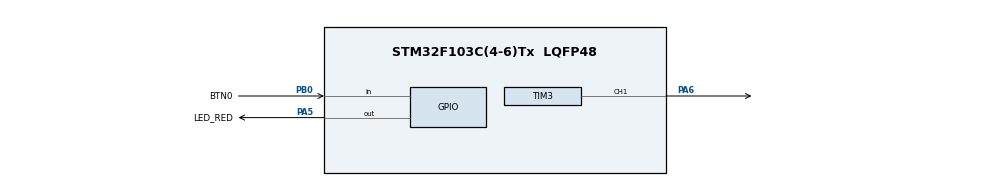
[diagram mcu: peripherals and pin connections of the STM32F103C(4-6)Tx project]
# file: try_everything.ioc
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Mcu.Family=STM32F1
Mcu.Name=STM32F103C(4-6)Tx
Mcu.Package=LQFP48
NVIC.PriorityGroup=NVIC_PRIORITYGROUP_4
NVIC.TIM2_IRQn=true\:0\:0\:false\:false\:true\:true\:true
NVIC.TIM3_IRQn=true\:0\:0\:false\:false\:true\:true\:true
PA5.GPIO_Label=LED_RED
PA5.Signal=GPIO_Output
PA6.Signal=S_TIM3_CH1
PB0.GPIO_Label=BTN0
PB0.Signal=GPIO_Input
PD0-OSC_IN.Mode=HSE-External-Oscillator
PD0-OSC_IN.Signal=RCC_OSC_IN
PD1-OSC_OUT.Mode=HSE-External-Oscillator
PD1-OSC_OUT.Signal=RCC_OSC_OUT
ProjectManager.HeapSize=0x200
ProjectManager.StackSize=0x400
ProjectManager.TargetToolchain=STM32CubeIDE
RCC.APB1Freq_Value=8000000
RCC.APB2Freq_Value=8000000
SH.S_TIM3_CH1.0=TIM3_CH1,PWM Generation1 CH1
TIM2.Period=9
TIM2.Prescaler=7999
TIM3.Channel-PWM\ Generation1\ CH1=TIM_CHANNEL_1
TIM3.Period=999
TIM3.Prescaler=7
VP_SYS_VS_ND.Mode=No_Debug
VP_TIM2_VS_ClockSourceINT.Mode=Internal
VP_TIM3_VS_ClockSourceINT.Mode=Internal
board=custom

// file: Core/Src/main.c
/* USER CODE BEGIN Header */
/**
  ******************************************************************************
  * @file           : main.c
  * @brief          : Main program body
  ******************************************************************************
  * @attention
  *
  * Copyright (c) 2021 STMicroelectronics.
  * All rights reserved.
  *
  * This software is licensed under terms that can be found in the LICENSE file
  * in the root directory of this software component.
  * If no LICENSE file comes with this software, it is provided AS-IS.
  *
  ******************************************************************************
  */
/* USER CODE END Header */
#include "main.h"

/* USER CODE BEGIN Includes */
#include "timer.h"
#include "button.h"
#include <stdio.h>
/* USER CODE END Includes */

/* USER CODE BEGIN PTD */
#define	OFF	 1
#define	DIM	 2
#define	MED	 3
#define	MAX	 4

static int led_state = OFF;
/* USER CODE END PTD */

TIM_HandleTypeDef htim2;
TIM_HandleTypeDef htim3;

void SystemClock_Config(void);
static void MX_GPIO_Init(void);
static void MX_TIM2_Init(void);
static void MX_TIM3_Init(void);

/* USER CODE BEGIN 0 */

void LED_LIGHT(int level) {
	switch(level) {
	case 0:
		__HAL_TIM_SetCompare(&htim3,TIM_CHANNEL_1,999);
		break;
	case 1:
		__HAL_TIM_SetCompare(&htim3,TIM_CHANNEL_1,749);
		break;
	case 2:
		__HAL_TIM_SetCompare(&htim3,TIM_CHANNEL_1,499);
		break;
	case 3:
		__HAL_TIM_SetCompare(&htim3,TIM_CHANNEL_1,0);
		break;
	}
}

void fsm_light() {
	switch(led_state) {
	case OFF:
		LED_LIGHT(0);
		if (get_button_value(0) == PRESS && get_button_delay(0) == 0) {
			set_button_delay(0);
			led_state = DIM;
		}
		break;
	case DIM:
		LED_LIGHT(1);
		if (get_button_value(0) == PRESS && get_button_delay(0) == 0) {
			set_button_delay(0);
			led_state = MED;
		}
		if (get_button_value(1) == PRESS) {
			led_state = OFF;
		}
		break;
	case MED:
		LED_LIGHT(2);
		if (get_button_value(0) == PRESS && get_button_delay(0) == 0) {
			set_button_delay(0);
			led_state = MAX;
		}
		if (get_button_value(1) == PRESS) {
			led_state = OFF;
		}
		break;
	case MAX:
		LED_LIGHT(3);
		if (get_button_value(0) == PRESS && get_button_delay(0) == 0) {
			set_button_delay(0);
			led_state = DIM;
		}
		if (get_button_value(1) == PRESS) {
			led_state = OFF;
		}
		break;
	}
}

int main(void)
{

  /* MCU Configuration--------------------------------------------------------*/

  /* Reset of all peripherals, Initializes the Flash interface and the Systick. */
  HAL_Init();

  /* Configure the system clock */
  SystemClock_Config();

  /* Initialize all configured peripherals */
  MX_GPIO_Init();
  MX_TIM2_Init();
  MX_TIM3_Init();
  /* USER CODE BEGIN 2 */
  //DUNG TIMER THI PHAI CO CAI NAY!
  HAL_TIM_Base_Start_IT(&htim2);
  HAL_TIM_PWM_Start(&htim3, TIM_CHANNEL_1);

  /* USER CODE END 2 */

  /* Infinite loop */
  /* USER CODE BEGIN WHILE */

  init_timer(0);
  init_timer(1);

  while (1) {

	  if (get_timer_flag(1) == 1) {
		  HAL_GPIO_TogglePin(GPIOA, LED_RED_Pin);
		  set_timer(1, 1000, 10);
	  }
	  if (get_timer_flag(0) == 1) {
		  read_button();
		  fsm_light();
		  set_timer(0, 10, 10);
	  }
  }
  /* USER CODE END 3 */
}

void SystemClock_Config(void)
{
  RCC_OscInitTypeDef RCC_OscInitStruct = {0};
  RCC_ClkInitTypeDef RCC_ClkInitStruct = {0};

  /** Initializes the RCC Oscillators according to the specified parameters
  * in the RCC_OscInitTypeDef structure.
  */
  RCC_OscInitStruct.OscillatorType = RCC_OSCILLATORTYPE_HSI;
  RCC_OscInitStruct.HSIState = RCC_HSI_ON;
  RCC_OscInitStruct.HSICalibrationValue = RCC_HSICALIBRATION_DEFAULT;
  RCC_OscInitStruct.PLL.PLLState = RCC_PLL_NONE;
  if (HAL_RCC_OscConfig(&RCC_OscInitStruct) != HAL_OK)
  {
    Error_Handler();
  }
  /** Initializes the CPU, AHB and APB buses clocks
  */
  RCC_ClkInitStruct.ClockType = RCC_CLOCKTYPE_HCLK|RCC_CLOCKTYPE_SYSCLK
                              |RCC_CLOCKTYPE_PCLK1|RCC_CLOCKTYPE_PCLK2;
  RCC_ClkInitStruct.SYSCLKSource = RCC_SYSCLKSOURCE_HSI;
  RCC_ClkInitStruct.AHBCLKDivider = RCC_SYSCLK_DIV1;
  RCC_ClkInitStruct.APB1CLKDivider = RCC_HCLK_DIV1;
  RCC_ClkInitStruct.APB2CLKDivider = RCC_HCLK_DIV1;

  if (HAL_RCC_ClockConfig(&RCC_ClkInitStruct, FLASH_LATENCY_0) != HAL_OK)
  {
    Error_Handler();
  }
}

static void MX_TIM2_Init(void)
{

  TIM_ClockConfigTypeDef sClockSourceConfig = {0};
  TIM_MasterConfigTypeDef sMasterConfig = {0};

  htim2.Instance = TIM2;
  htim2.Init.Prescaler = 7999;
  htim2.Init.CounterMode = TIM_COUNTERMODE_UP;
  htim2.Init.Period = 9;
  htim2.Init.ClockDivision = TIM_CLOCKDIVISION_DIV1;
  htim2.Init.AutoReloadPreload = TIM_AUTORELOAD_PRELOAD_DISABLE;
  if (HAL_TIM_Base_Init(&htim2) != HAL_OK)
  {
    Error_Handler();
  }
  sClockSourceConfig.ClockSource = TIM_CLOCKSOURCE_INTERNAL;
  if (HAL_TIM_ConfigClockSource(&htim2, &sClockSourceConfig) != HAL_OK)
  {
    Error_Handler();
  }
  sMasterConfig.MasterOutputTrigger = TIM_TRGO_RESET;
  sMasterConfig.MasterSlaveMode = TIM_MASTERSLAVEMODE_DISABLE;
  if (HAL_TIMEx_MasterConfigSynchronization(&htim2, &sMasterConfig) != HAL_OK)
  {
    Error_Handler();
  }

}

static void MX_TIM3_Init(void)
{

  TIM_ClockConfigTypeDef sClockSourceConfig = {0};
  TIM_MasterConfigTypeDef sMasterConfig = {0};
  TIM_OC_InitTypeDef sConfigOC = {0};

  htim3.Instance = TIM3;
  htim3.Init.Prescaler = 7;
  htim3.Init.CounterMode = TIM_COUNTERMODE_UP;
  htim3.Init.Period = 999;
  htim3.Init.ClockDivision = TIM_CLOCKDIVISION_DIV1;
  htim3.Init.AutoReloadPreload = TIM_AUTORELOAD_PRELOAD_DISABLE;
  if (HAL_TIM_Base_Init(&htim3) != HAL_OK)
  {
    Error_Handler();
  }
  sClockSourceConfig.ClockSource = TIM_CLOCKSOURCE_INTERNAL;
  if (HAL_TIM_ConfigClockSource(&htim3, &sClockSourceConfig) != HAL_OK)
  {
    Error_Handler();
  }
  if (HAL_TIM_PWM_Init(&htim3) != HAL_OK)
  {
    Error_Handler();
  }
  sMasterConfig.MasterOutputTrigger = TIM_TRGO_RESET;
  sMasterConfig.MasterSlaveMode = TIM_MASTERSLAVEMODE_DISABLE;
  if (HAL_TIMEx_MasterConfigSynchronization(&htim3, &sMasterConfig) != HAL_OK)
  {
    Error_Handler();
  }
  sConfigOC.OCMode = TIM_OCMODE_PWM1;
  sConfigOC.Pulse = 0;
  sConfigOC.OCPolarity = TIM_OCPOLARITY_HIGH;
  sConfigOC.OCFastMode = TIM_OCFAST_DISABLE;
  if (HAL_TIM_PWM_ConfigChannel(&htim3, &sConfigOC, TIM_CHANNEL_1) != HAL_OK)
  {
    Error_Handler();
  }
  HAL_TIM_MspPostInit(&htim3);

}

static void MX_GPIO_Init(void)
{
  GPIO_InitTypeDef GPIO_InitStruct = {0};

  /* GPIO Ports Clock Enable */
  __HAL_RCC_GPIOD_CLK_ENABLE();
  __HAL_RCC_GPIOA_CLK_ENABLE();
  __HAL_RCC_GPIOB_CLK_ENABLE();

  /*Configure GPIO pin Output Level */
  HAL_GPIO_WritePin(LED_RED_GPIO_Port, LED_RED_Pin, GPIO_PIN_RESET);

  /*Configure GPIO pin : LED_RED_Pin */
  GPIO_InitStruct.Pin = LED_RED_Pin;
  GPIO_InitStruct.Mode = GPIO_MODE_OUTPUT_PP;
  GPIO_InitStruct.Pull = GPIO_NOPULL;
  GPIO_InitStruct.Speed = GPIO_SPEED_FREQ_LOW;
  HAL_GPIO_Init(LED_RED_GPIO_Port, &GPIO_InitStruct);

  /*Configure GPIO pin : BTN0_Pin */
  GPIO_InitStruct.Pin = BTN0_Pin;
  GPIO_InitStruct.Mode = GPIO_MODE_INPUT;
  GPIO_InitStruct.Pull = GPIO_NOPULL;
  HAL_GPIO_Init(BTN0_GPIO_Port, &GPIO_InitStruct);

}

/* USER CODE BEGIN 4 */

void HAL_TIM_PeriodElapsedCallback(TIM_HandleTypeDef *htim) {
//	if (htim->Instance == TIM2) {
//		run_timer(0);
//	}
//	problem 2: tim3 prescaller: 399, counter: 9 => global interrupt enable: 2000Hz, moi 1 lan interrupt la 0.5ms
//	if (htim->Instance == TIM3) {
//		HAL_GPIO_TogglePin(GPIOA, LED_RED_Pin);
//	}

//	problem 4:
//	timer2: xung vuong 10Hz tao xung 20Hz
//	=> tinh nhanh prescaller va counter = 8*10^6 / pre * count = 10 =>
//	prescaller = 3999 va counter = 99.
//	timer3: xung vuong 100Hz tao xung 200Hz => prescaller = 399 va counter = 99
//	if (htim->Instance == TIM2) {
//		HAL_GPIO_TogglePin(GPIOA, PD1_Pin);
//	}
//	if (htim->Instance == TIM3) {
//		HAL_GPIO_TogglePin(GPIOA, PD7_Pin);
//	}
// 	hoac, su dung soft timer de chay!
	if (htim->Instance == TIM2) {
		run_timer(0);
		run_timer(1);
	}

}

/* USER CODE END 4 */

void Error_Handler(void)
{
  __disable_irq();
  while (1)
  {
  }
}
